VERSION ""

NS_ :

BS_:

BU_:

BO_ 394 DIN0_3: 8 Vector__XXX
 SG_ DIN0_3 : 0|8@1+ (1,0) [0|0] "" Vector__XXX

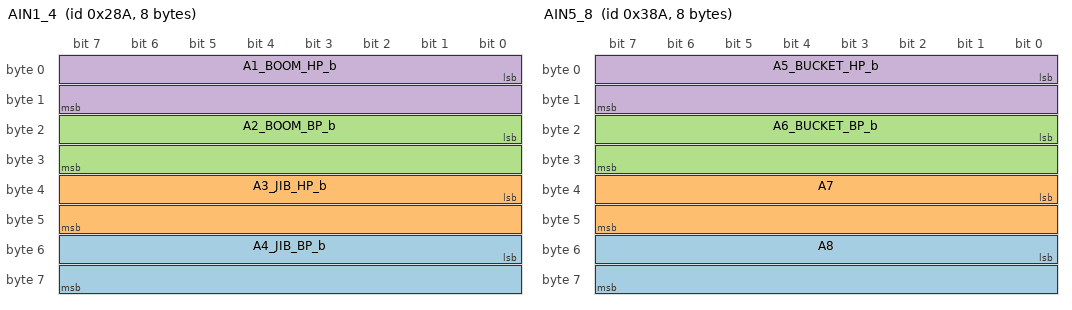
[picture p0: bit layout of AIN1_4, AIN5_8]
BO_ 650 AIN1_4: 8 Vector__XXX
 SG_ A4_JIB_BP_b : 48|16@1- (0.015320069339859434,-99.99999999999997) [0|0] "" Vector__XXX
 SG_ A3_JIB_HP_b : 32|16@1- (0.015320069339859434,-99.99999999999997) [0|0] "" Vector__XXX
 SG_ A2_BOOM_BP_b : 16|16@1- (0.015320069339859434,-99.99999999999997) [0|0] "" Vector__XXX
 SG_ A1_BOOM_HP_b : 0|16@1- (0.015320069339859434,-99.99999999999997) [0|0] "" Vector__XXX

BO_ 906 AIN5_8: 8 Vector__XXX
 SG_ A8 : 48|16@1- (1,0) [0|0] "" Vector__XXX
 SG_ A7 : 32|16@1- (1,0) [0|0] "" Vector__XXX
 SG_ A6_BUCKET_BP_b : 16|16@1- (0.015320069339859434,-99.99999999999997) [0|0] "" Vector__XXX
 SG_ A5_BUCKET_HP_b : 0|16@1- (0.015320069339859434,-99.99999999999997) [0|0] "" Vector__XXX

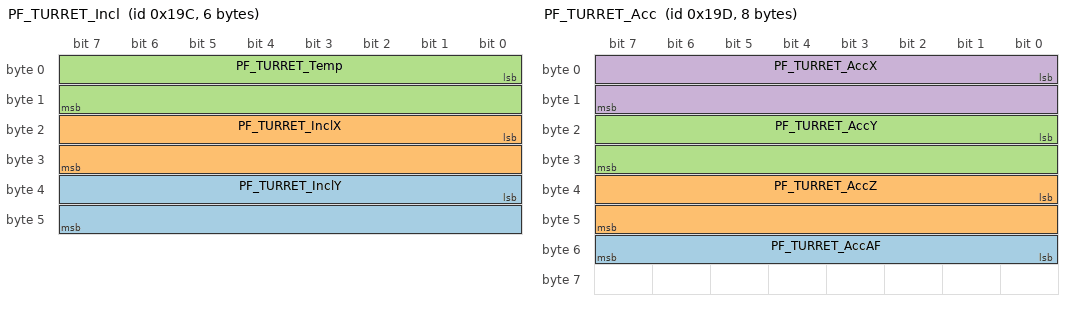
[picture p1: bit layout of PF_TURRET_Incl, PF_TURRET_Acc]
BO_ 412 PF_TURRET_Incl: 6 Vector__XXX
 SG_ PF_TURRET_InclY : 32|16@1- (0.01,0) [0|0] "" Vector__XXX
 SG_ PF_TURRET_InclX : 16|16@1- (0.01,0) [0|0] "" Vector__XXX
 SG_ PF_TURRET_Temp : 0|16@1- (1,0) [0|0] "" Vector__XXX

BO_ 413 PF_TURRET_Acc: 8 Vector__XXX
 SG_ PF_TURRET_AccAF : 48|8@1+ (1,0) [0|0] "" Vector__XXX
 SG_ PF_TURRET_AccZ : 32|16@1- (0.001,0) [0|0] "" Vector__XXX
 SG_ PF_TURRET_AccY : 16|16@1- (0.001,0) [0|0] "" Vector__XXX
 SG_ PF_TURRET_AccX : 0|16@1- (0.001,0) [0|0] "" Vector__XXX

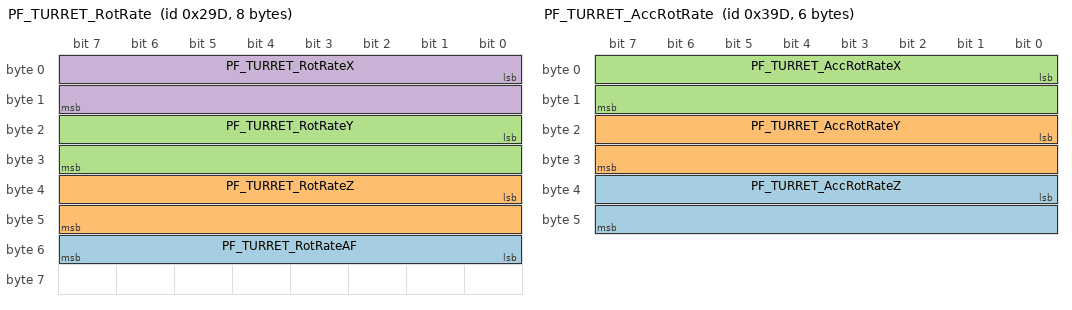
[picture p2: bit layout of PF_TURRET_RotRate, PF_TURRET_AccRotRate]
BO_ 669 PF_TURRET_RotRate: 8 Vector__XXX
 SG_ PF_TURRET_RotRateAF : 48|8@1+ (1,0) [0|0] "" Vector__XXX
 SG_ PF_TURRET_RotRateZ : 32|16@1- (0.01,0) [0|0] "" Vector__XXX
 SG_ PF_TURRET_RotRateY : 16|16@1- (0.01,0) [0|0] "" Vector__XXX
 SG_ PF_TURRET_RotRateX : 0|16@1- (0.01,0) [0|0] "" Vector__XXX

BO_ 925 PF_TURRET_AccRotRate: 6 Vector__XXX
 SG_ PF_TURRET_AccRotRateZ : 32|16@1- (1,0) [0|0] "" Vector__XXX
 SG_ PF_TURRET_AccRotRateY : 16|16@1- (1,0) [0|0] "" Vector__XXX
 SG_ PF_TURRET_AccRotRateX : 0|16@1- (1,0) [0|0] "" Vector__XXX

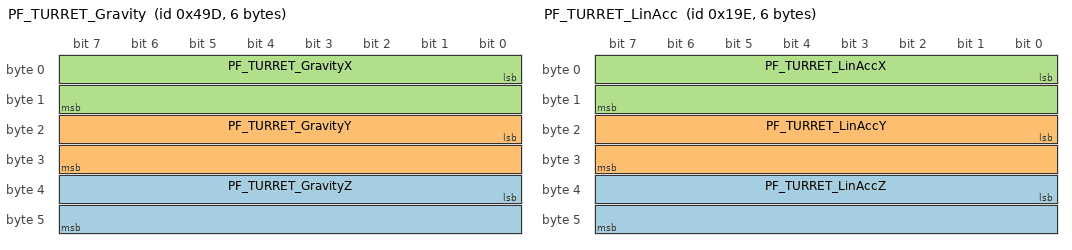
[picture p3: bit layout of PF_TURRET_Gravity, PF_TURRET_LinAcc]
BO_ 1181 PF_TURRET_Gravity: 6 Vector__XXX
 SG_ PF_TURRET_GravityZ : 32|16@1- (0.001,0) [0|0] "" Vector__XXX
 SG_ PF_TURRET_GravityY : 16|16@1- (0.001,0) [0|0] "" Vector__XXX
 SG_ PF_TURRET_GravityX : 0|16@1- (0.001,0) [0|0] "" Vector__XXX

BO_ 414 PF_TURRET_LinAcc: 6 Vector__XXX
 SG_ PF_TURRET_LinAccZ : 32|16@1- (0.001,0) [0|0] "" Vector__XXX
 SG_ PF_TURRET_LinAccY : 16|16@1- (0.001,0) [0|0] "" Vector__XXX
 SG_ PF_TURRET_LinAccX : 0|16@1- (0.001,0) [0|0] "" Vector__XXX

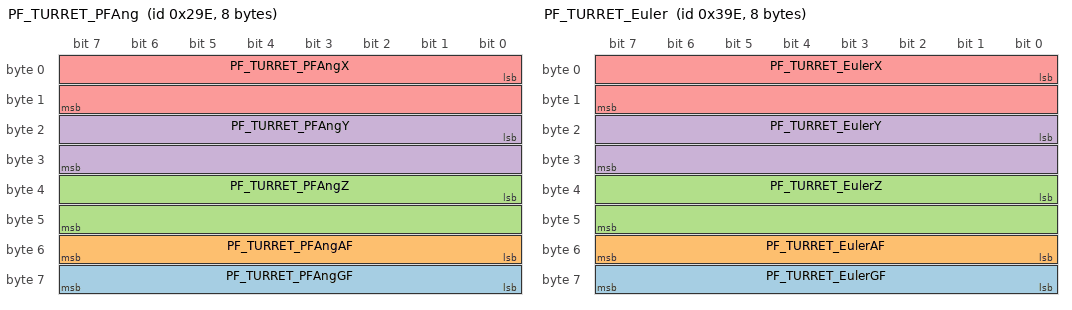
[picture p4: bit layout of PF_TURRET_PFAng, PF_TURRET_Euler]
BO_ 670 PF_TURRET_PFAng: 8 Vector__XXX
 SG_ PF_TURRET_PFAngGF : 56|8@1+ (1,0) [0|0] "" Vector__XXX
 SG_ PF_TURRET_PFAngAF : 48|8@1+ (1,0) [0|0] "" Vector__XXX
 SG_ PF_TURRET_PFAngZ : 32|16@1+ (0.01,0) [0|0] "" Vector__XXX
 SG_ PF_TURRET_PFAngY : 16|16@1+ (0.01,0) [0|0] "" Vector__XXX
 SG_ PF_TURRET_PFAngX : 0|16@1+ (0.01,0) [0|0] "" Vector__XXX

BO_ 926 PF_TURRET_Euler: 8 Vector__XXX
 SG_ PF_TURRET_EulerGF : 56|8@1+ (1,0) [0|0] "" Vector__XXX
 SG_ PF_TURRET_EulerAF : 48|8@1+ (1,0) [0|0] "" Vector__XXX
 SG_ PF_TURRET_EulerZ : 32|16@1- (0.01,0) [0|0] "" Vector__XXX
 SG_ PF_TURRET_EulerY : 16|16@1- (0.01,0) [0|0] "" Vector__XXX
 SG_ PF_TURRET_EulerX : 0|16@1- (0.01,0) [0|0] "" Vector__XXX

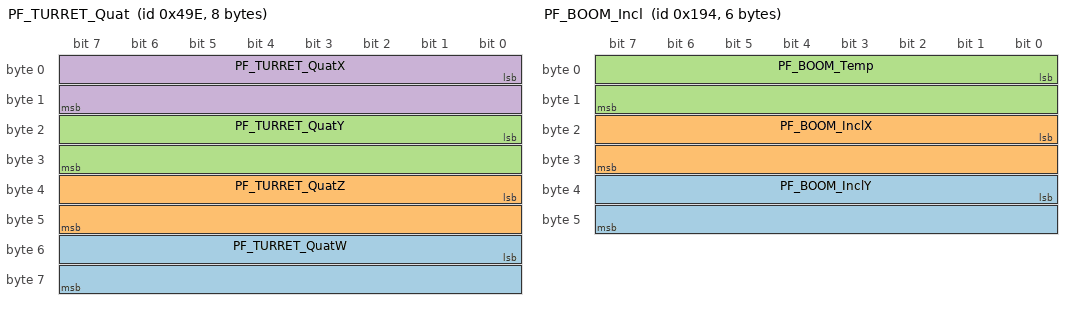
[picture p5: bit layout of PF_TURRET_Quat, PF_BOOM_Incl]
BO_ 1182 PF_TURRET_Quat: 8 Vector__XXX
 SG_ PF_TURRET_QuatW : 48|16@1- (0.001,0) [0|0] "" Vector__XXX
 SG_ PF_TURRET_QuatZ : 32|16@1- (0.001,0) [0|0] "" Vector__XXX
 SG_ PF_TURRET_QuatY : 16|16@1- (0.001,0) [0|0] "" Vector__XXX
 SG_ PF_TURRET_QuatX : 0|16@1- (0.001,0) [0|0] "" Vector__XXX

BO_ 415 PF_TURRET_Temp: 4 Vector__XXX
 SG_ PF_TURRET_TempMain : 16|16@1- (0.1,0) [0|0] "" Vector__XXX
 SG_ PF_TURRET_TempMems : 0|16@1- (0.1,0) [0|0] "" Vector__XXX

BO_ 404 PF_BOOM_Incl: 6 Vector__XXX
 SG_ PF_BOOM_InclY : 32|16@1- (0.01,0) [0|0] "" Vector__XXX
 SG_ PF_BOOM_InclX : 16|16@1- (0.01,0) [0|0] "" Vector__XXX
 SG_ PF_BOOM_Temp : 0|16@1- (1,0) [0|0] "" Vector__XXX

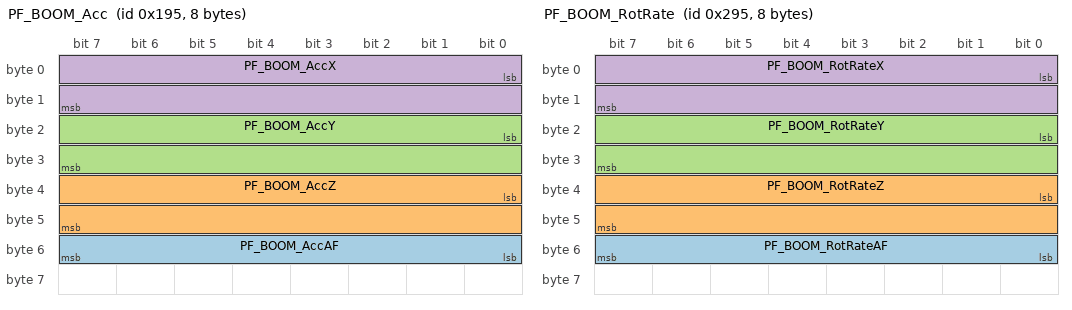
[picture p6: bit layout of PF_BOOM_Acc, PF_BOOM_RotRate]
BO_ 405 PF_BOOM_Acc: 8 Vector__XXX
 SG_ PF_BOOM_AccAF : 48|8@1+ (1,0) [0|0] "" Vector__XXX
 SG_ PF_BOOM_AccZ : 32|16@1- (0.001,0) [0|0] "" Vector__XXX
 SG_ PF_BOOM_AccY : 16|16@1- (0.001,0) [0|0] "" Vector__XXX
 SG_ PF_BOOM_AccX : 0|16@1- (0.001,0) [0|0] "" Vector__XXX

BO_ 661 PF_BOOM_RotRate: 8 Vector__XXX
 SG_ PF_BOOM_RotRateAF : 48|8@1+ (1,0) [0|0] "" Vector__XXX
 SG_ PF_BOOM_RotRateZ : 32|16@1- (0.01,0) [0|0] "" Vector__XXX
 SG_ PF_BOOM_RotRateY : 16|16@1- (0.01,0) [0|0] "" Vector__XXX
 SG_ PF_BOOM_RotRateX : 0|16@1- (0.01,0) [0|0] "" Vector__XXX

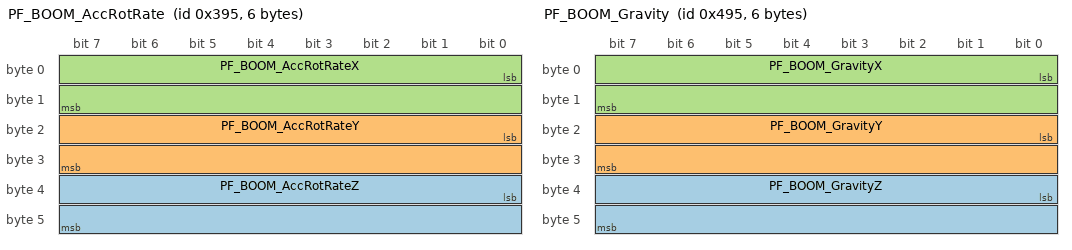
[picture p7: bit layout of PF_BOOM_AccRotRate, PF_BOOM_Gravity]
BO_ 917 PF_BOOM_AccRotRate: 6 Vector__XXX
 SG_ PF_BOOM_AccRotRateZ : 32|16@1- (1,0) [0|0] "" Vector__XXX
 SG_ PF_BOOM_AccRotRateY : 16|16@1- (1,0) [0|0] "" Vector__XXX
 SG_ PF_BOOM_AccRotRateX : 0|16@1- (1,0) [0|0] "" Vector__XXX

BO_ 1173 PF_BOOM_Gravity: 6 Vector__XXX
 SG_ PF_BOOM_GravityZ : 32|16@1- (0.001,0) [0|0] "" Vector__XXX
 SG_ PF_BOOM_GravityY : 16|16@1- (0.001,0) [0|0] "" Vector__XXX
 SG_ PF_BOOM_GravityX : 0|16@1- (0.001,0) [0|0] "" Vector__XXX

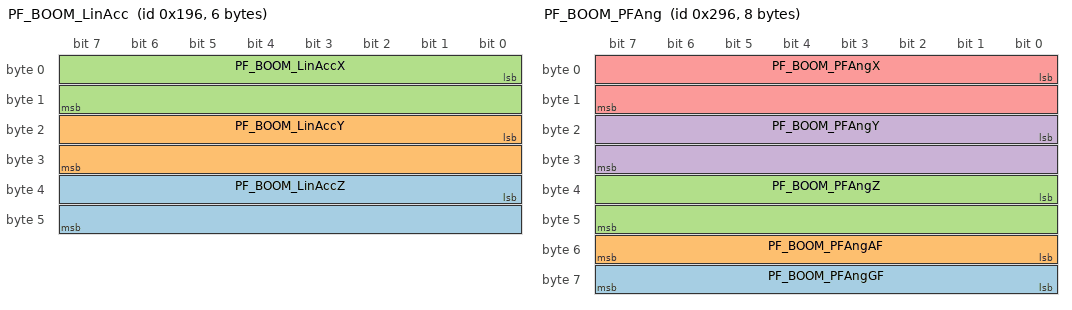
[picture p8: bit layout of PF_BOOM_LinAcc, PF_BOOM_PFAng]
BO_ 406 PF_BOOM_LinAcc: 6 Vector__XXX
 SG_ PF_BOOM_LinAccZ : 32|16@1- (0.001,0) [0|0] "" Vector__XXX
 SG_ PF_BOOM_LinAccY : 16|16@1- (0.001,0) [0|0] "" Vector__XXX
 SG_ PF_BOOM_LinAccX : 0|16@1- (0.001,0) [0|0] "" Vector__XXX

BO_ 662 PF_BOOM_PFAng: 8 Vector__XXX
 SG_ PF_BOOM_PFAngGF : 56|8@1+ (1,0) [0|0] "" Vector__XXX
 SG_ PF_BOOM_PFAngAF : 48|8@1+ (1,0) [0|0] "" Vector__XXX
 SG_ PF_BOOM_PFAngZ : 32|16@1+ (0.01,0) [0|0] "" Vector__XXX
 SG_ PF_BOOM_PFAngY : 16|16@1+ (0.01,0) [0|0] "" Vector__XXX
 SG_ PF_BOOM_PFAngX : 0|16@1+ (0.01,0) [0|0] "" Vector__XXX

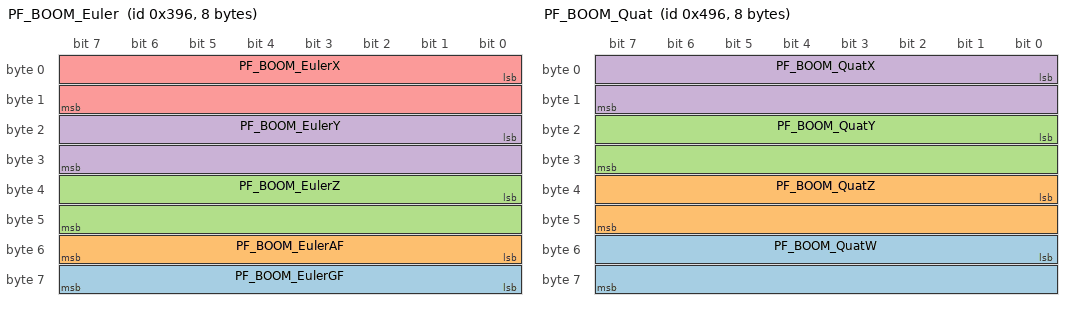
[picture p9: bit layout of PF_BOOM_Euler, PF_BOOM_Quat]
BO_ 918 PF_BOOM_Euler: 8 Vector__XXX
 SG_ PF_BOOM_EulerGF : 56|8@1+ (1,0) [0|0] "" Vector__XXX
 SG_ PF_BOOM_EulerAF : 48|8@1+ (1,0) [0|0] "" Vector__XXX
 SG_ PF_BOOM_EulerZ : 32|16@1- (0.01,0) [0|0] "" Vector__XXX
 SG_ PF_BOOM_EulerY : 16|16@1- (0.01,0) [0|0] "" Vector__XXX
 SG_ PF_BOOM_EulerX : 0|16@1- (0.01,0) [0|0] "" Vector__XXX

BO_ 1174 PF_BOOM_Quat: 8 Vector__XXX
 SG_ PF_BOOM_QuatW : 48|16@1- (0.001,0) [0|0] "" Vector__XXX
 SG_ PF_BOOM_QuatZ : 32|16@1- (0.001,0) [0|0] "" Vector__XXX
 SG_ PF_BOOM_QuatY : 16|16@1- (0.001,0) [0|0] "" Vector__XXX
 SG_ PF_BOOM_QuatX : 0|16@1- (0.001,0) [0|0] "" Vector__XXX

BO_ 407 PF_BOOM_Temp: 4 Vector__XXX
 SG_ PF_BOOM_TempMain : 16|16@1- (0.1,0) [0|0] "" Vector__XXX
 SG_ PF_BOOM_TempMems : 0|16@1- (0.1,0) [0|0] "" Vector__XXX

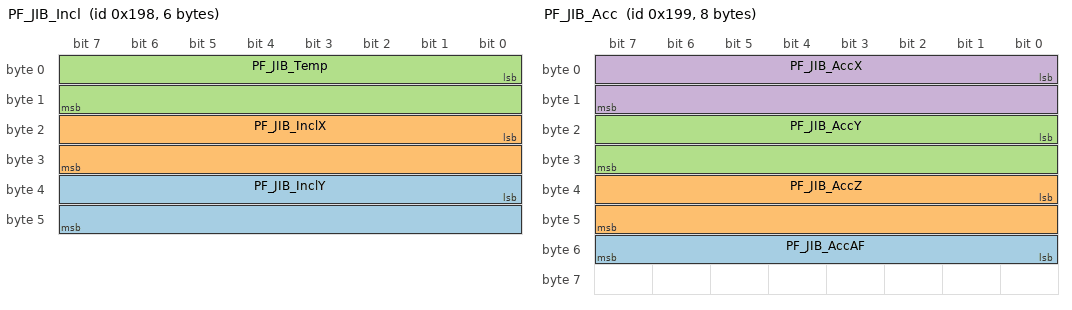
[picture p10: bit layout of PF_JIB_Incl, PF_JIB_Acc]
BO_ 408 PF_JIB_Incl: 6 Vector__XXX
 SG_ PF_JIB_InclY : 32|16@1- (0.01,0) [0|0] "" Vector__XXX
 SG_ PF_JIB_InclX : 16|16@1- (0.01,0) [0|0] "" Vector__XXX
 SG_ PF_JIB_Temp : 0|16@1- (1,0) [0|0] "" Vector__XXX

BO_ 409 PF_JIB_Acc: 8 Vector__XXX
 SG_ PF_JIB_AccAF : 48|8@1+ (1,0) [0|0] "" Vector__XXX
 SG_ PF_JIB_AccZ : 32|16@1- (0.001,0) [0|0] "" Vector__XXX
 SG_ PF_JIB_AccY : 16|16@1- (0.001,0) [0|0] "" Vector__XXX
 SG_ PF_JIB_AccX : 0|16@1- (0.001,0) [0|0] "" Vector__XXX

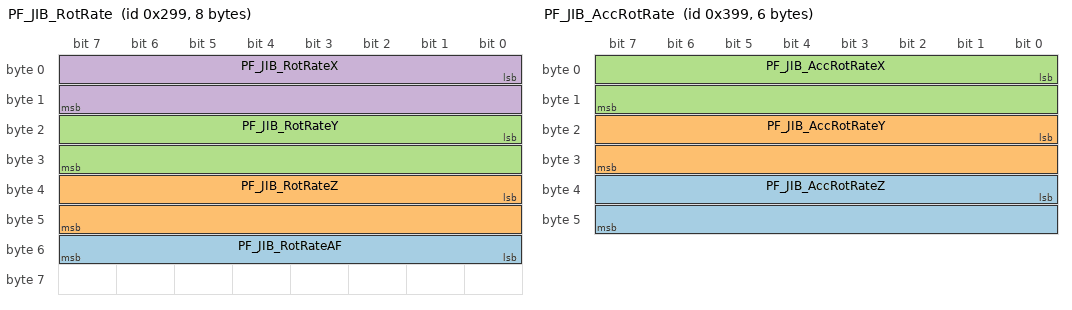
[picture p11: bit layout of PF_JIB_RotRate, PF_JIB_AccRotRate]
BO_ 665 PF_JIB_RotRate: 8 Vector__XXX
 SG_ PF_JIB_RotRateAF : 48|8@1+ (1,0) [0|0] "" Vector__XXX
 SG_ PF_JIB_RotRateZ : 32|16@1- (0.01,0) [0|0] "" Vector__XXX
 SG_ PF_JIB_RotRateY : 16|16@1- (0.01,0) [0|0] "" Vector__XXX
 SG_ PF_JIB_RotRateX : 0|16@1- (0.01,0) [0|0] "" Vector__XXX

BO_ 921 PF_JIB_AccRotRate: 6 Vector__XXX
 SG_ PF_JIB_AccRotRateZ : 32|16@1- (1,0) [0|0] "" Vector__XXX
 SG_ PF_JIB_AccRotRateY : 16|16@1- (1,0) [0|0] "" Vector__XXX
 SG_ PF_JIB_AccRotRateX : 0|16@1- (1,0) [0|0] "" Vector__XXX

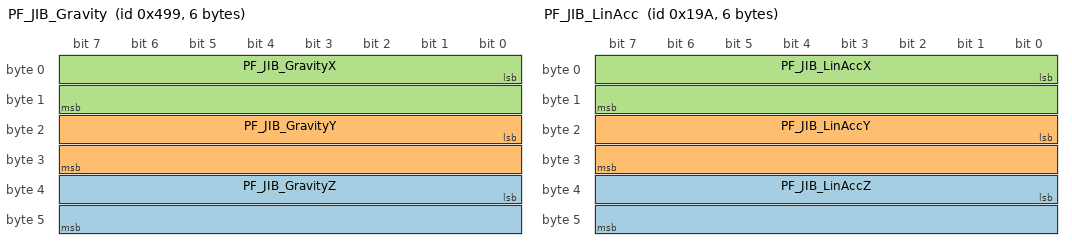
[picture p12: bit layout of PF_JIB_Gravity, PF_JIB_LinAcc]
BO_ 1177 PF_JIB_Gravity: 6 Vector__XXX
 SG_ PF_JIB_GravityZ : 32|16@1- (0.001,0) [0|0] "" Vector__XXX
 SG_ PF_JIB_GravityY : 16|16@1- (0.001,0) [0|0] "" Vector__XXX
 SG_ PF_JIB_GravityX : 0|16@1- (0.001,0) [0|0] "" Vector__XXX

BO_ 410 PF_JIB_LinAcc: 6 Vector__XXX
 SG_ PF_JIB_LinAccZ : 32|16@1- (0.001,0) [0|0] "" Vector__XXX
 SG_ PF_JIB_LinAccY : 16|16@1- (0.001,0) [0|0] "" Vector__XXX
 SG_ PF_JIB_LinAccX : 0|16@1- (0.001,0) [0|0] "" Vector__XXX

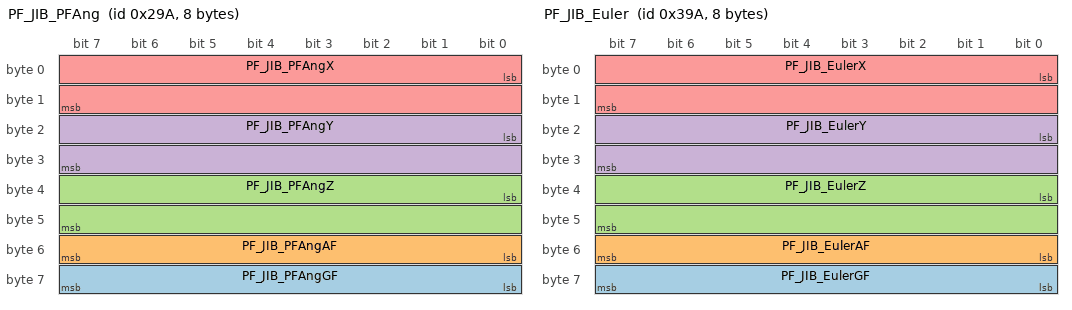
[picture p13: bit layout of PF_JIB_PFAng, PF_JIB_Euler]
BO_ 666 PF_JIB_PFAng: 8 Vector__XXX
 SG_ PF_JIB_PFAngGF : 56|8@1+ (1,0) [0|0] "" Vector__XXX
 SG_ PF_JIB_PFAngAF : 48|8@1+ (1,0) [0|0] "" Vector__XXX
 SG_ PF_JIB_PFAngZ : 32|16@1+ (0.01,0) [0|0] "" Vector__XXX
 SG_ PF_JIB_PFAngY : 16|16@1+ (0.01,0) [0|0] "" Vector__XXX
 SG_ PF_JIB_PFAngX : 0|16@1+ (0.01,0) [0|0] "" Vector__XXX

BO_ 922 PF_JIB_Euler: 8 Vector__XXX
 SG_ PF_JIB_EulerGF : 56|8@1+ (1,0) [0|0] "" Vector__XXX
 SG_ PF_JIB_EulerAF : 48|8@1+ (1,0) [0|0] "" Vector__XXX
 SG_ PF_JIB_EulerZ : 32|16@1- (0.01,0) [0|0] "" Vector__XXX
 SG_ PF_JIB_EulerY : 16|16@1- (0.01,0) [0|0] "" Vector__XXX
 SG_ PF_JIB_EulerX : 0|16@1- (0.01,0) [0|0] "" Vector__XXX

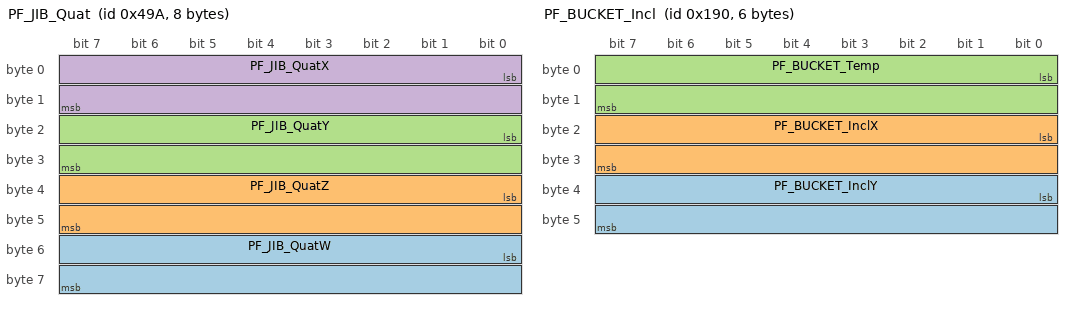
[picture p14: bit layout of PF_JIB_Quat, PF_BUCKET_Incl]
BO_ 1178 PF_JIB_Quat: 8 Vector__XXX
 SG_ PF_JIB_QuatW : 48|16@1- (0.001,0) [0|0] "" Vector__XXX
 SG_ PF_JIB_QuatZ : 32|16@1- (0.001,0) [0|0] "" Vector__XXX
 SG_ PF_JIB_QuatY : 16|16@1- (0.001,0) [0|0] "" Vector__XXX
 SG_ PF_JIB_QuatX : 0|16@1- (0.001,0) [0|0] "" Vector__XXX

BO_ 411 PF_JIB_Temp: 4 Vector__XXX
 SG_ PF_JIB_TempMain : 16|16@1- (0.1,0) [0|0] "" Vector__XXX
 SG_ PF_JIB_TempMems : 0|16@1- (0.1,0) [0|0] "" Vector__XXX

BO_ 400 PF_BUCKET_Incl: 6 Vector__XXX
 SG_ PF_BUCKET_InclY : 32|16@1- (0.01,0) [0|0] "" Vector__XXX
 SG_ PF_BUCKET_InclX : 16|16@1- (0.01,0) [0|0] "" Vector__XXX
 SG_ PF_BUCKET_Temp : 0|16@1- (1,0) [0|0] "" Vector__XXX

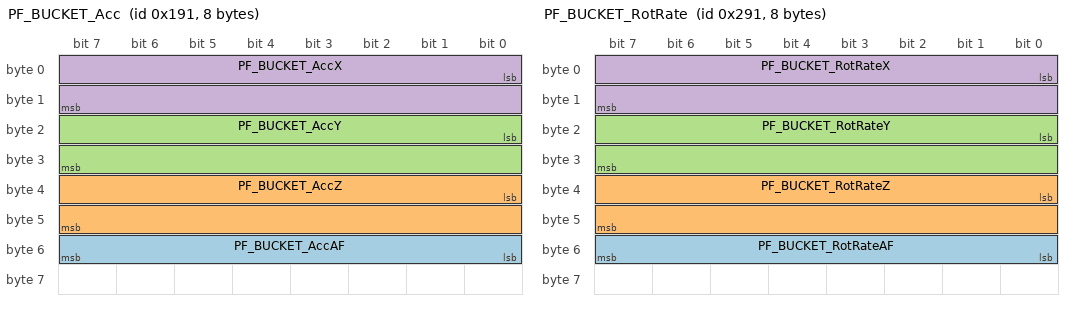
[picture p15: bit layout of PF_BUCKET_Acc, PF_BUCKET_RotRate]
BO_ 401 PF_BUCKET_Acc: 8 Vector__XXX
 SG_ PF_BUCKET_AccAF : 48|8@1+ (1,0) [0|0] "" Vector__XXX
 SG_ PF_BUCKET_AccZ : 32|16@1- (0.001,0) [0|0] "" Vector__XXX
 SG_ PF_BUCKET_AccY : 16|16@1- (0.001,0) [0|0] "" Vector__XXX
 SG_ PF_BUCKET_AccX : 0|16@1- (0.001,0) [0|0] "" Vector__XXX

BO_ 657 PF_BUCKET_RotRate: 8 Vector__XXX
 SG_ PF_BUCKET_RotRateAF : 48|8@1+ (1,0) [0|0] "" Vector__XXX
 SG_ PF_BUCKET_RotRateZ : 32|16@1- (0.01,0) [0|0] "" Vector__XXX
 SG_ PF_BUCKET_RotRateY : 16|16@1- (0.01,0) [0|0] "" Vector__XXX
 SG_ PF_BUCKET_RotRateX : 0|16@1- (0.01,0) [0|0] "" Vector__XXX

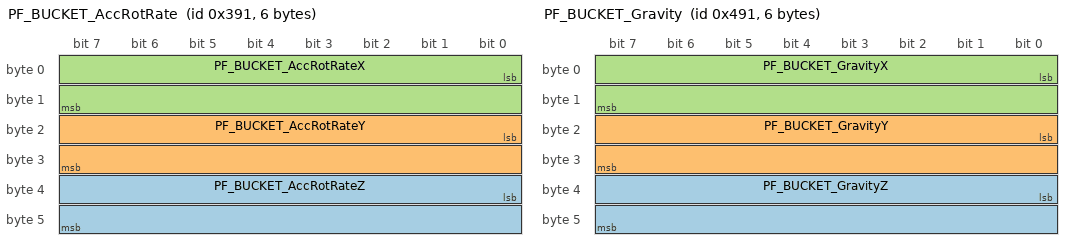
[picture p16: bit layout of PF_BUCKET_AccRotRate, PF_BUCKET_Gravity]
BO_ 913 PF_BUCKET_AccRotRate: 6 Vector__XXX
 SG_ PF_BUCKET_AccRotRateZ : 32|16@1- (1,0) [0|0] "" Vector__XXX
 SG_ PF_BUCKET_AccRotRateY : 16|16@1- (1,0) [0|0] "" Vector__XXX
 SG_ PF_BUCKET_AccRotRateX : 0|16@1- (1,0) [0|0] "" Vector__XXX

BO_ 1169 PF_BUCKET_Gravity: 6 Vector__XXX
 SG_ PF_BUCKET_GravityZ : 32|16@1- (0.001,0) [0|0] "" Vector__XXX
 SG_ PF_BUCKET_GravityY : 16|16@1- (0.001,0) [0|0] "" Vector__XXX
 SG_ PF_BUCKET_GravityX : 0|16@1- (0.001,0) [0|0] "" Vector__XXX

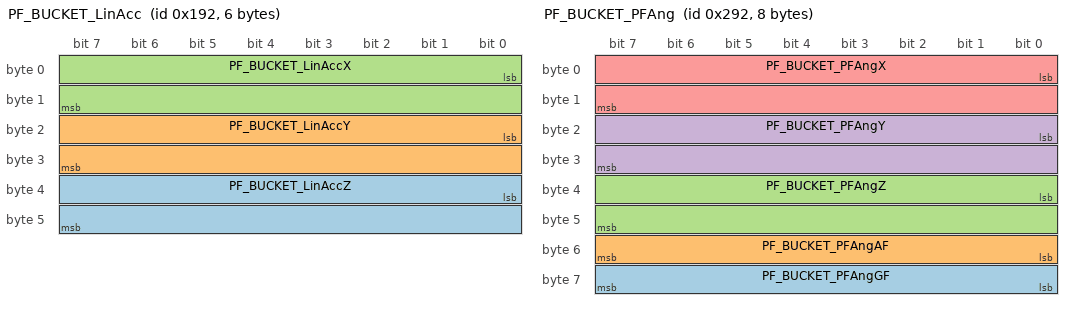
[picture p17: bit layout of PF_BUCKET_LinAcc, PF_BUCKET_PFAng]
BO_ 402 PF_BUCKET_LinAcc: 6 Vector__XXX
 SG_ PF_BUCKET_LinAccZ : 32|16@1- (0.001,0) [0|0] "" Vector__XXX
 SG_ PF_BUCKET_LinAccY : 16|16@1- (0.001,0) [0|0] "" Vector__XXX
 SG_ PF_BUCKET_LinAccX : 0|16@1- (0.001,0) [0|0] "" Vector__XXX

BO_ 658 PF_BUCKET_PFAng: 8 Vector__XXX
 SG_ PF_BUCKET_PFAngGF : 56|8@1+ (1,0) [0|0] "" Vector__XXX
 SG_ PF_BUCKET_PFAngAF : 48|8@1+ (1,0) [0|0] "" Vector__XXX
 SG_ PF_BUCKET_PFAngZ : 32|16@1+ (0.01,0) [0|0] "" Vector__XXX
 SG_ PF_BUCKET_PFAngY : 16|16@1+ (0.01,0) [0|0] "" Vector__XXX
 SG_ PF_BUCKET_PFAngX : 0|16@1+ (0.01,0) [0|0] "" Vector__XXX

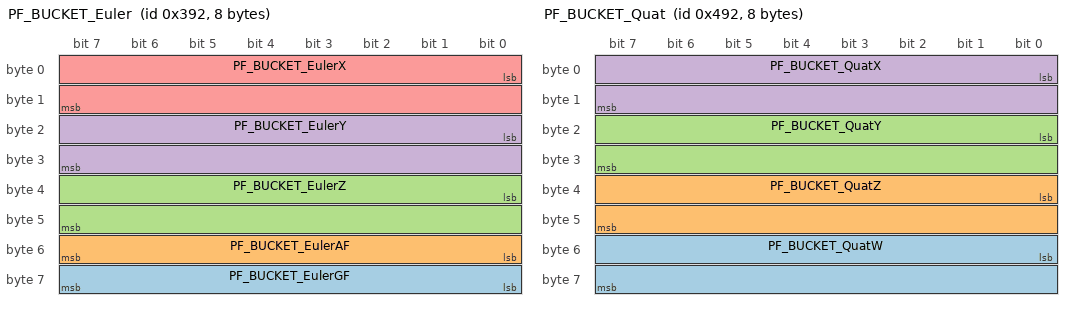
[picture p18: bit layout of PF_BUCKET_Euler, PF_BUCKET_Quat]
BO_ 914 PF_BUCKET_Euler: 8 Vector__XXX
 SG_ PF_BUCKET_EulerGF : 56|8@1+ (1,0) [0|0] "" Vector__XXX
 SG_ PF_BUCKET_EulerAF : 48|8@1+ (1,0) [0|0] "" Vector__XXX
 SG_ PF_BUCKET_EulerZ : 32|16@1- (0.01,0) [0|0] "" Vector__XXX
 SG_ PF_BUCKET_EulerY : 16|16@1- (0.01,0) [0|0] "" Vector__XXX
 SG_ PF_BUCKET_EulerX : 0|16@1- (0.01,0) [0|0] "" Vector__XXX

BO_ 1170 PF_BUCKET_Quat: 8 Vector__XXX
 SG_ PF_BUCKET_QuatW : 48|16@1- (0.001,0) [0|0] "" Vector__XXX
 SG_ PF_BUCKET_QuatZ : 32|16@1- (0.001,0) [0|0] "" Vector__XXX
 SG_ PF_BUCKET_QuatY : 16|16@1- (0.001,0) [0|0] "" Vector__XXX
 SG_ PF_BUCKET_QuatX : 0|16@1- (0.001,0) [0|0] "" Vector__XXX

BO_ 403 PF_BUCKET_Temp: 4 Vector__XXX
 SG_ PF_BUCKET_TempMain : 16|16@1- (0.1,0) [0|0] "" Vector__XXX
 SG_ PF_BUCKET_TempMems : 0|16@1- (0.1,0) [0|0] "" Vector__XXX
